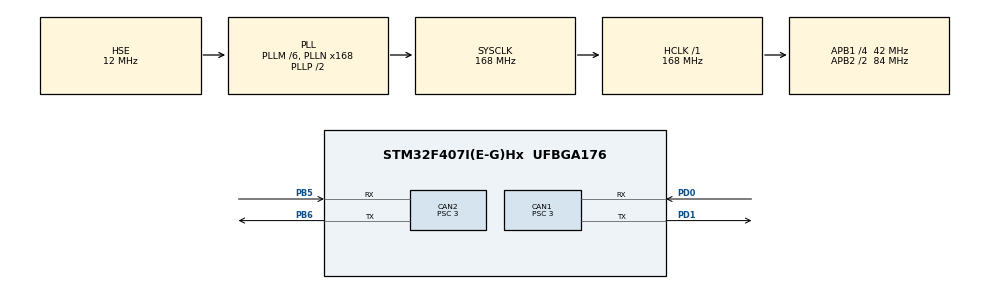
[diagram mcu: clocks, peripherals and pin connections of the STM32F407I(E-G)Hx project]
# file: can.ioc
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CAN1.BS1=CAN_BS1_10TQ
CAN1.BS2=CAN_BS2_3TQ
CAN1.CalculateBaudRate=1000000
CAN1.CalculateTimeQuantum=71.42857142857143
CAN1.Prescaler=3
CAN2.BS1=CAN_BS1_10TQ
CAN2.BS2=CAN_BS2_3TQ
CAN2.CalculateBaudRate=1000000
CAN2.CalculateTimeQuantum=71.42857142857143
CAN2.Prescaler=3
Mcu.Family=STM32F4
Mcu.Name=STM32F407I(E-G)Hx
Mcu.Package=UFBGA176
NVIC.CAN1_RX0_IRQn=true\:0\:0\:false\:false\:true\:true\:true\:true
NVIC.CAN2_RX0_IRQn=true\:0\:0\:false\:false\:true\:true\:true\:true
NVIC.PriorityGroup=NVIC_PRIORITYGROUP_4
PA13.Mode=Serial_Wire
PA13.Signal=SYS_JTMS-SWDIO
PA14.Mode=Serial_Wire
PA14.Signal=SYS_JTCK-SWCLK
PB5.Mode=CAN_Activate
PB5.Signal=CAN2_RX
PB6.Mode=CAN_Activate
PB6.Signal=CAN2_TX
PD0.Mode=CAN_Activate
PD0.Signal=CAN1_RX
PD1.Mode=CAN_Activate
PD1.Signal=CAN1_TX
PH0-OSC_IN.Mode=HSE-External-Oscillator
PH0-OSC_IN.Signal=RCC_OSC_IN
PH1-OSC_OUT.Mode=HSE-External-Oscillator
PH1-OSC_OUT.Signal=RCC_OSC_OUT
ProjectManager.HeapSize=0x200
ProjectManager.StackSize=0x400
ProjectManager.TargetToolchain=CMake
RCC.48MHZClocksFreq_Value=84000000
RCC.AHBFreq_Value=168000000
RCC.APB1CLKDivider=RCC_HCLK_DIV4
RCC.APB1Freq_Value=42000000
RCC.APB1TimFreq_Value=84000000
RCC.APB2CLKDivider=RCC_HCLK_DIV2
RCC.APB2Freq_Value=84000000
RCC.APB2TimFreq_Value=168000000
RCC.CortexFreq_Value=168000000
RCC.HCLKFreq_Value=168000000
RCC.HSE_VALUE=12000000
RCC.HSI_VALUE=16000000
RCC.LSE_VALUE=32768
RCC.PLLM=6
RCC.PLLN=168
RCC.PLLSourceVirtual=RCC_PLLSOURCE_HSE
RCC.SYSCLKFreq_VALUE=168000000
RCC.SYSCLKSource=RCC_SYSCLKSOURCE_PLLCLK
RCC.VCOOutputFreq_Value=336000000
board=custom

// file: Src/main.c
/* USER CODE BEGIN Header */
/**
  ******************************************************************************
  * @file           : main.c
  * @brief          : Main program body
  ******************************************************************************
  * @attention
  *
  * Copyright (c) 2026 STMicroelectronics.
  * All rights reserved.
  *
  * This software is licensed under terms that can be found in the LICENSE file
  * in the root directory of this software component.
  * If no LICENSE file comes with this software, it is provided AS-IS.
  *
  ******************************************************************************
  */
/* USER CODE END Header */
#include "main.h"
#include "can.h"
#include "gpio.h"

/* USER CODE BEGIN Includes */
#include "CAN_receive.h"
/* USER CODE END Includes */

/* USER CODE BEGIN PD */
int16_t current_ecd = 0.0f ;
int16_t target_ecd = 0.0f ;
int16_t error_sum = 0.0f ;
int16_t last_error = 0.0f ;

float target_angle = 0.0f ;
float debug_angle_deg = 0.0f ;

float kp = 23.0f ;
float ki = 0.05f ;
float kd = 23.0f ;
/* USER CODE END PD */

void SystemClock_Config(void);

int main(void)
{

  /* MCU Configuration--------------------------------------------------------*/

  /* Reset of all peripherals, Initializes the Flash interface and the Systick. */
  HAL_Init();

  /* Configure the system clock */
  SystemClock_Config();

  /* Initialize all configured peripherals */
  MX_GPIO_Init();
  MX_CAN1_Init();
  MX_CAN2_Init();

  /* Infinite loop */
  while (1)
  {
    current_ecd = get_yaw_gimbal_motor_measure_point()->ecd;
    debug_angle_deg = (float)current_ecd / 8192.0f * 360.0f;
    target_ecd = target_angle / 360.0f * 8192.0f;

    //过零点处理
    int16_t error = target_ecd - current_ecd;
    if (error > 4096) error -= 8192;
    if (error < -4096) error += 8192;

    error_sum = error_sum + error;
    if (error_sum > 10000) error_sum = 10000;
    if (error_sum < -10000) error_sum = -10000;
    float output = kp * error + ki * error_sum + kd * (error - last_error);

    if (output > 10000) output = 10000;
    if (output < -10000) output = -10000;

    CAN_cmd_gimbal((int16_t)output, 0, 0, 0);
    last_error = error;
  }
}

void SystemClock_Config(void)
{
  RCC_OscInitTypeDef RCC_OscInitStruct = {0};
  RCC_ClkInitTypeDef RCC_ClkInitStruct = {0};

  /** Configure the main internal regulator output voltage
  */
  __HAL_RCC_PWR_CLK_ENABLE();
  __HAL_PWR_VOLTAGESCALING_CONFIG(PWR_REGULATOR_VOLTAGE_SCALE1);

  /** Initializes the RCC Oscillators according to the specified parameters
  * in the RCC_OscInitTypeDef structure.
  */
  RCC_OscInitStruct.OscillatorType = RCC_OSCILLATORTYPE_HSE;
  RCC_OscInitStruct.HSEState = RCC_HSE_ON;
  RCC_OscInitStruct.PLL.PLLState = RCC_PLL_ON;
  RCC_OscInitStruct.PLL.PLLSource = RCC_PLLSOURCE_HSE;
  RCC_OscInitStruct.PLL.PLLM = 6;
  RCC_OscInitStruct.PLL.PLLN = 168;
  RCC_OscInitStruct.PLL.PLLP = RCC_PLLP_DIV2;
  RCC_OscInitStruct.PLL.PLLQ = 4;
  if (HAL_RCC_OscConfig(&RCC_OscInitStruct) != HAL_OK)
  {
    Error_Handler();
  }

  /** Initializes the CPU, AHB and APB buses clocks
  */
  RCC_ClkInitStruct.ClockType = RCC_CLOCKTYPE_HCLK|RCC_CLOCKTYPE_SYSCLK
                              |RCC_CLOCKTYPE_PCLK1|RCC_CLOCKTYPE_PCLK2;
  RCC_ClkInitStruct.SYSCLKSource = RCC_SYSCLKSOURCE_PLLCLK;
  RCC_ClkInitStruct.AHBCLKDivider = RCC_SYSCLK_DIV1;
  RCC_ClkInitStruct.APB1CLKDivider = RCC_HCLK_DIV4;
  RCC_ClkInitStruct.APB2CLKDivider = RCC_HCLK_DIV2;

  if (HAL_RCC_ClockConfig(&RCC_ClkInitStruct, FLASH_LATENCY_5) != HAL_OK)
  {
    Error_Handler();
  }
}

void Error_Handler(void)
{
  __disable_irq();
  while (1)
  {
  }
}
